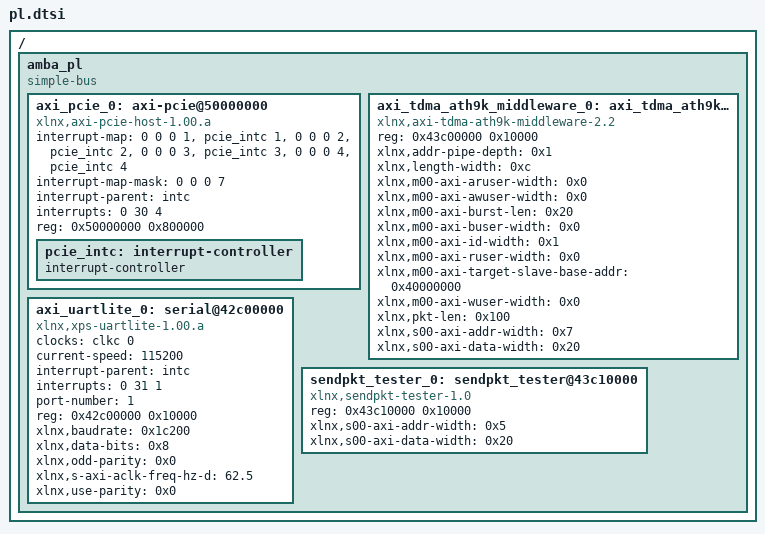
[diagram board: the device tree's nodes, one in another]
/*
 * CAUTION: This file is automatically generated by Xilinx.
 * Version: HSI 2016.2
 * Today is: Mon Jul 30 16:23:45 2018
*/


/ {
	amba_pl: amba_pl {
		#address-cells = <1>;
		#size-cells = <1>;
		compatible = "simple-bus";
		ranges ;
		axi_pcie_0: axi-pcie@50000000 {
			#address-cells = <3>;
			#interrupt-cells = <1>;
			#size-cells = <2>;
			compatible = "xlnx,axi-pcie-host-1.00.a";
			device_type = "pci";
			interrupt-map = <0 0 0 1 &pcie_intc 1>,
					<0 0 0 2 &pcie_intc 2>,
					<0 0 0 3 &pcie_intc 3>, 
					<0 0 0 4 &pcie_intc 4>;
			interrupt-map-mask = <0 0 0 7>;
			interrupt-parent = <&intc>;
			interrupts = <0 30 4>;
			ranges = <0x02000000 0x00000000 0x60000000 0x60000000 0x00000000 0x02000000>;
			reg = <0x50000000 0x800000>;
			pcie_intc: interrupt-controller {
				#address-cells = <0>;
				#interrupt-cells = <1>;
				interrupt-controller ;
			};
		};
		axi_tdma_ath9k_middleware_0: axi_tdma_ath9k_middleware@43c00000 {
			compatible = "xlnx,axi-tdma-ath9k-middleware-2.2";
			reg = <0x43c00000 0x10000>;
			xlnx,addr-pipe-depth = <0x1>;
			xlnx,length-width = <0xc>;
			xlnx,m00-axi-aruser-width = <0x0>;
			xlnx,m00-axi-awuser-width = <0x0>;
			xlnx,m00-axi-burst-len = <0x20>;
			xlnx,m00-axi-buser-width = <0x0>;
			xlnx,m00-axi-id-width = <0x1>;
			xlnx,m00-axi-ruser-width = <0x0>;
			xlnx,m00-axi-target-slave-base-addr = <0x40000000>;
			xlnx,m00-axi-wuser-width = <0x0>;
			xlnx,pkt-len = <0x100>;
			xlnx,s00-axi-addr-width = <0x7>;
			xlnx,s00-axi-data-width = <0x20>;
		};
		axi_uartlite_0: serial@42c00000 {
			clock-names = "ref_clk";
			clocks = <&clkc 0>;
			compatible = "xlnx,xps-uartlite-1.00.a";
			current-speed = <115200>;
			device_type = "serial";
			interrupt-parent = <&intc>;
			interrupts = <0 31 1>;
			port-number = <1>;
			reg = <0x42c00000 0x10000>;
			xlnx,baudrate = <0x1c200>;
			xlnx,data-bits = <0x8>;
			xlnx,odd-parity = <0x0>;
			xlnx,s-axi-aclk-freq-hz-d = "62.5";
			xlnx,use-parity = <0x0>;
		};
		sendpkt_tester_0: sendpkt_tester@43c10000 {
			compatible = "xlnx,sendpkt-tester-1.0";
			reg = <0x43c10000 0x10000>;
			xlnx,s00-axi-addr-width = <0x5>;
			xlnx,s00-axi-data-width = <0x20>;
		};
	};
};
